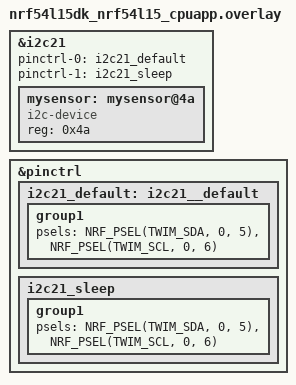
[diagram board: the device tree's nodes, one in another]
// To get started, press Ctrl+Space to bring up the completion menu and view the available nodes.
// For more help, browse the DeviceTree documentation at https://docs.zephyrproject.org/latest/guides/dts/index.html

&i2c21 {
    status = "okay";
    pinctrl-0 = <&i2c21_default>;
	pinctrl-1 = <&i2c21_sleep>;
    pinctrl-names = "default", "sleep";
    mysensor: mysensor@4a{
        compatible = "i2c-device";
        status = "okay";
        reg = < 0x4a >;
    };
};

&pinctrl {
	/omit-if-no-ref/ i2c21_default: i2c21__default {
		group1 {
			psels = <NRF_PSEL(TWIM_SDA, 0, 5)>,
				    <NRF_PSEL(TWIM_SCL, 0, 6)>;
		};
	};
    /omit-if-no-ref/ i2c21_sleep: i2c21_sleep {
		group1 {
			psels = <NRF_PSEL(TWIM_SDA, 0, 5)>,
				    <NRF_PSEL(TWIM_SCL, 0, 6)>;
		};
	};
};
